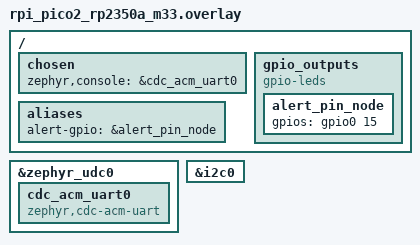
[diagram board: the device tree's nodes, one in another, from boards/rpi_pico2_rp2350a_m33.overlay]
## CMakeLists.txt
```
cmake_minimum_required(VERSION 3.20.0)

find_package(Zephyr REQUIRED HINTS $ENV{ZEPHYR_BASE})

project(hum-light-sensor)

set(CMAKE_EXPORT_COMPILE_COMMANDS ON)

target_sources(app PRIVATE 
    src/main.c 
    src/inc/light-sensor/light-sensor.c 
    src/inc/humidity-sensor/humidity-sensor.c
)

FILE(GLOB SRC_FILES "src/*.c")
target_sources(app PRIVATE ${SRC_FILES})
```

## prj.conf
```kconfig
CONFIG_SERIAL=y
CONFIG_CONSOLE=y
CONFIG_I2C=y
CONFIG_UART_CONSOLE=y
CONFIG_STDOUT_CONSOLE=y
CONFIG_UART_LINE_CTRL=y
CONFIG_CBPRINTF_FP_SUPPORT=y

CONFIG_USB_DEVICE_STACK_NEXT=y
CONFIG_CDC_ACM_SERIAL_INITIALIZE_AT_BOOT=y
CONFIG_CDC_ACM_SERIAL_PRODUCT_STRING="USBD console sample"
```

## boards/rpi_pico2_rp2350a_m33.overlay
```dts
/ {
    chosen {
        zephyr,console = &cdc_acm_uart0;
    };

    aliases {
        alert-gpio = &alert_pin_node;
    };

    gpio_outputs {
        compatible = "gpio-leds";       /* gives DTC the binding it needs */
        alert_pin_node: alert_pin_node {
            gpios = <&gpio0 15 0>;      /* 0 = GPIO_ACTIVE_HIGH */
        };
    };
};

&zephyr_udc0 {
    cdc_acm_uart0: cdc_acm_uart0 {
        compatible = "zephyr,cdc-acm-uart";
    };
};

&i2c0 {
    status = "okay";
};
```

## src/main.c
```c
#include "inc/humidity-sensor/humidity-sensor.h"
#include "inc/light-sensor/light-sensor.h"

extern struct k_sem low_light_sem; 
static const struct device *i2c_bus;
static struct k_thread light_alert_thread_data;

#define LIGHT_ALERT_STACK_SIZE 1024
#define ALERT_PIN_NODE DT_ALIAS(alert_gpio)

K_THREAD_STACK_DEFINE(light_alert_stack, LIGHT_ALERT_STACK_SIZE);
static const struct gpio_dt_spec alert_pin = GPIO_DT_SPEC_GET(ALERT_PIN_NODE, gpios);

static void light_alert_thread(void *a, void *b, void *c) {
    while (1) {
        k_sem_take(&low_light_sem, K_FOREVER);

        printk("Alert: light level too low!\n");
        
        gpio_pin_set_dt(&alert_pin, 1);
        k_msleep(100);
        gpio_pin_set_dt(&alert_pin, 0);
    }
}

int main(void) {
    i2c_bus = DEVICE_DT_GET(DT_NODELABEL(i2c0));

    init_light_sensor(i2c_bus);
    init_humidity_sensor(i2c_bus);

    k_thread_create(&light_alert_thread_data, light_alert_stack,
                    K_THREAD_STACK_SIZEOF(light_alert_stack),
                    light_alert_thread,
                    NULL, NULL, NULL,
                    5, 0, K_NO_WAIT);

    while (1) {
        read_light_sensor(i2c_bus);
        read_humidity_sensor(i2c_bus);
        k_msleep(1000);
    }
}
```
